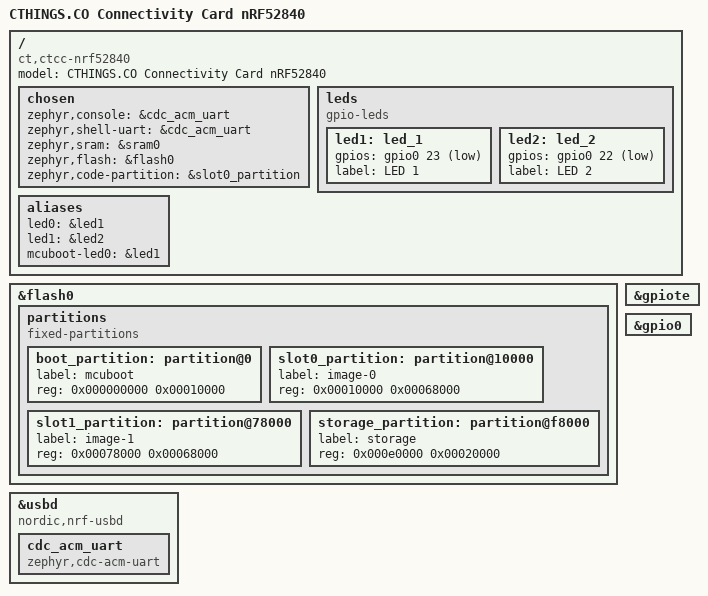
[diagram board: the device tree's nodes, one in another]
/*
 * Copyright (c) 2024 CTHINGS.CO
 *
 * SPDX-License-Identifier: Apache-2.0
 */

/dts-v1/;
#include <nordic/nrf52840_qiaa.dtsi>

/ {
	model = "CTHINGS.CO Connectivity Card nRF52840";
	compatible = "ct,ctcc-nrf52840";

	chosen {
		zephyr,console = &cdc_acm_uart;
		zephyr,shell-uart = &cdc_acm_uart;
		zephyr,sram = &sram0;
		zephyr,flash = &flash0;
		zephyr,code-partition = &slot0_partition;
	};

	leds {
		 compatible = "gpio-leds";
		 led1: led_1 {
			 gpios = <&gpio0 23 GPIO_ACTIVE_LOW>;
			 label = "LED 1";
		 };
		 led2: led_2 {
			 gpios = <&gpio0 22 GPIO_ACTIVE_LOW>;
			 label = "LED 2";
		 };
	};

	aliases {
		led0 = &led1;
		led1 = &led2;
		mcuboot-led0 = &led1;
	};
};

&flash0 {

	partitions {
		compatible = "fixed-partitions";
		#address-cells = <1>;
		#size-cells = <1>;

		boot_partition: partition@0 {
			label = "mcuboot";
			reg = <0x000000000 0x00010000>;
		};
		slot0_partition: partition@10000 {
			label = "image-0";
			reg = <0x00010000 0x00068000>;
		};
		slot1_partition: partition@78000 {
			label = "image-1";
			reg = <0x00078000 0x00068000>;
		};
		storage_partition: partition@f8000 {
			label = "storage";
			reg = <0x000e0000 0x00020000>;
		};
	};
};

&gpiote {
	status = "okay";
};

&gpio0 {
	status = "okay";
};

zephyr_udc0: &usbd {
	compatible = "nordic,nrf-usbd";
	status = "okay";

	cdc_acm_uart: cdc_acm_uart {
		compatible = "zephyr,cdc-acm-uart";
	};
};
